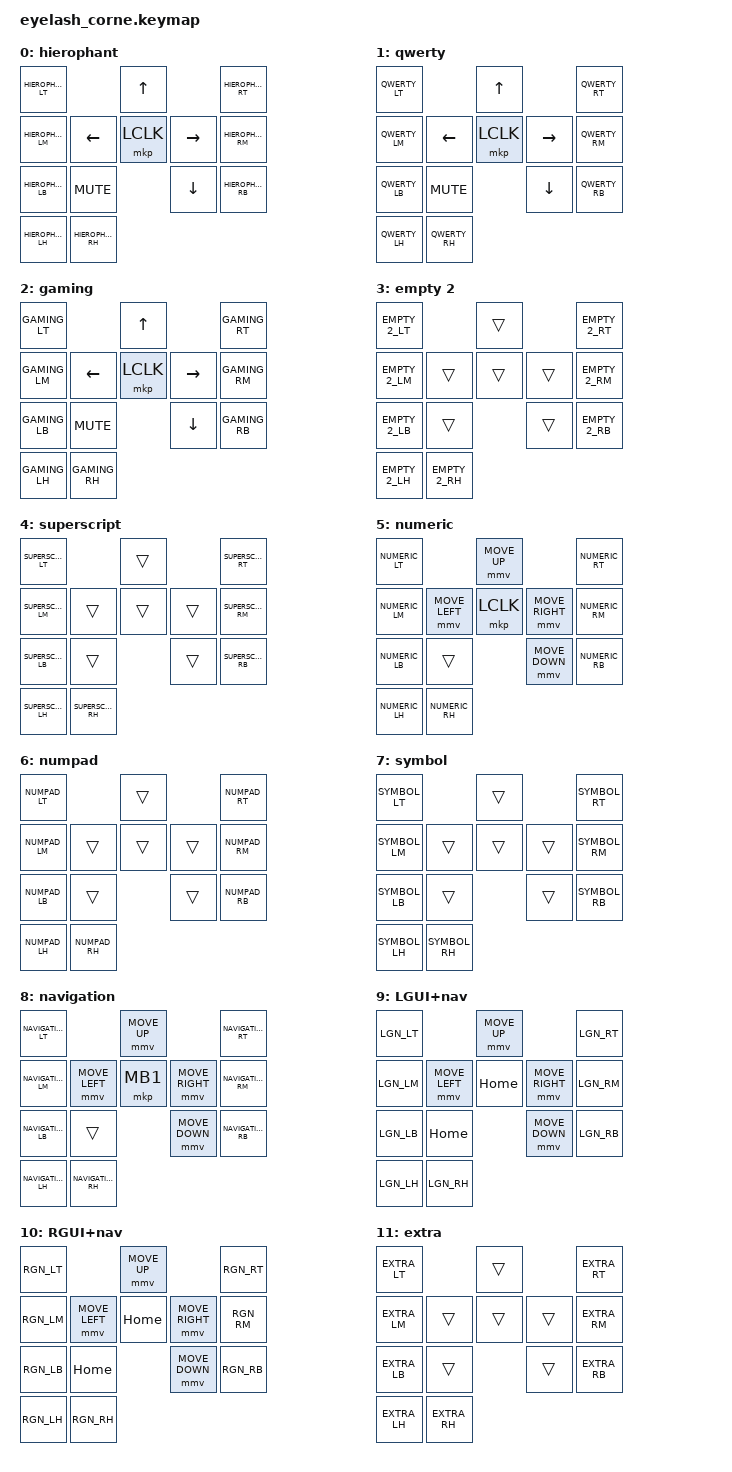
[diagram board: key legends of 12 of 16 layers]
#define INNER_CLUSTER JS0 LEC JS1 JS2 JS3 JS4

#define CONFIG_WIRELESS
#define ZMK_BASE_LAYER(name, LT, RT, LM, RM, LB, RB, LH, RH, INNER_CLUSTER)    \
    ZMK_LAYER(                                                                 \
        name,                                                                  \
                 LT RT                                                         \
                 LM RM                                                         \
                 LB RB                                                         \
                 LH RH                                                         \
	                JS0							       \
        LEC     JS1 JS2 JS3						       \
		            JS4							       \
    )

#include "zmk-helpers/key-labels/eyelash42.h"
#include "jjb.keymap"

/ {
    keymap {
        compatible = "zmk,keymap";
	hierophant_layer {
				display-name = "hierophant";
				bindings = <
HIEROPHANT_LT                       &kp UP              HIEROPHANT_RT
HIEROPHANT_LM             &kp LEFT  &mkp LCLK &kp RIGHT HIEROPHANT_RM
HIEROPHANT_LB &kp C_MUTE            &kp DOWN            HIEROPHANT_RB
HIEROPHANT_LH HIEROPHANT_RH
				>;				
            sensor-bindings = <&inc_dec_kp C_VOLUME_UP C_VOLUME_DOWN>;
	};


        qwerty_layer {
            display-name = "qwerty";
            bindings = <
QWERTY_LT                       &kp UP              QWERTY_RT
QWERTY_LM             &kp LEFT  &mkp LCLK &kp RIGHT QWERTY_RM
QWERTY_LB &kp C_MUTE            &kp DOWN            QWERTY_RB
QWERTY_LH QWERTY_RH
				>;				
        };


        gaming_layer {
            display-name = "gaming";
            bindings = <
GAMING_LT                       &kp UP              GAMING_RT
GAMING_LM             &kp LEFT  &mkp LCLK &kp RIGHT GAMING_RM
GAMING_LB &kp C_MUTE            &kp DOWN            GAMING_RB
GAMING_LH GAMING_RH
             >;
            sensor-bindings = <&inc_dec_kp C_VOLUME_UP C_VOLUME_DOWN>;
        };


	empty_2_layer {
				display-name = "empty 2";
				bindings = <
EMPTY_2_LT                &trans        EMPTY_2_RT
EMPTY_2_LM         &trans &trans &trans EMPTY_2_RM
EMPTY_2_LB &trans         &trans        EMPTY_2_RB
EMPTY_2_LH EMPTY_2_RH
				>;				
	};


        superscript_layer {
            display-name = "superscript";
            bindings = <
SUPERSCRIPT_LT                  &trans          SUPERSCRIPT_RT
SUPERSCRIPT_LM          &trans  &trans  &trans  SUPERSCRIPT_RM
SUPERSCRIPT_LB  &trans          &trans          SUPERSCRIPT_RB
SUPERSCRIPT_LH SUPERSCRIPT_RH
            >;
        };


        numeric_layer {
            display-name = "numeric";
            bindings = <
NUMERIC_LT                        &mmv MOVE_UP                NUMERIC_RT
NUMERIC_LM         &mmv MOVE_LEFT &mkp LCLK  &mmv MOVE_RIGHT  NUMERIC_RM
NUMERIC_LB &trans                 &mmv MOVE_DOWN              NUMERIC_RB
NUMERIC_LH NUMERIC_RH
            >;
            sensor-bindings = <&scroll_encoder>;
        };


        numpad_layer {
            display-name = "numpad";
            bindings = <
NUMPAD_LT                  &trans          NUMPAD_RT
NUMPAD_LM          &trans  &trans  &trans  NUMPAD_RM
NUMPAD_LB  &trans          &trans          NUMPAD_RB
NUMPAD_LH NUMPAD_RH
            >;
        };


        symbol_layer {
            display-name = "symbol";
            bindings = <
SYMBOL_LT                  &trans          SYMBOL_RT
SYMBOL_LM          &trans  &trans  &trans  SYMBOL_RM
SYMBOL_LB  &trans          &trans          SYMBOL_RB
SYMBOL_LH SYMBOL_RH
            >;
        };


        navigation_layer {
            display-name = "navigation";
            bindings = <
NAVIGATION_LT                        &mmv MOVE_UP                NAVIGATION_RT
NAVIGATION_LM         &mmv MOVE_LEFT &mkp MB1   &mmv MOVE_RIGHT  NAVIGATION_RM
NAVIGATION_LB &trans                 &mmv MOVE_DOWN              NAVIGATION_RB
NAVIGATION_LH NAVIGATION_RH
            >;
            sensor-bindings = <&scroll_encoder>;
        };


        mod_l_nav_layer {
            display-name = "LGUI+nav";
            bindings = <
LGN_LT                          &mmv MOVE_UP                      LGN_RT
LGN_LM            &mmv MOVE_LEFT &kp HOME        &mmv MOVE_RIGHT  LGN_RM
LGN_LB  &kp HOME                &mmv MOVE_DOWN                    LGN_RB
LGN_LH LGN_RH
            >;
        };


        mod_r_nav_layer {
            display-name = "RGUI+nav";
            bindings = <
RGN_LT                          &mmv MOVE_UP                      RGN_RT
RGN_LM            &mmv MOVE_LEFT &kp HOME        &mmv MOVE_RIGHT  RGN_RM
RGN_LB  &kp HOME                &mmv MOVE_DOWN                    RGN_RB
RGN_LH RGN_RH
            >;
        };


        extra_layer {
            display-name = "extra";
            bindings = <
EXTRA_LT                &trans         EXTRA_RT
EXTRA_LM         &trans &trans &trans  EXTRA_RM
EXTRA_LB &trans         &trans         EXTRA_RB
EXTRA_LH EXTRA_RH
            >;
            sensor-bindings = <&scroll_encoder>;
        };


        function_layer {
            display-name = "function";
            bindings = <
FUNCTION_LT                        &mmv MOVE_UP                FUNCTION_RT
FUNCTION_LM         &mmv MOVE_LEFT &mkp MB1   &mmv MOVE_RIGHT  FUNCTION_RM
FUNCTION_LB &trans                 &mmv MOVE_DOWN              FUNCTION_RB
FUNCTION_LH FUNCTION_RH
            >;
            sensor-bindings = <&scroll_encoder>;
        };

        lighting_layer {
            display-name = "lighting";
            bindings = <
LIGHTING_LT                            &trans                          LIGHTING_RT
LIGHTING_LM              &trans        &to HIEROPHANT   &trans         LIGHTING_RM
LIGHTING_LB  LIGHT_TOG                 &trans                          LIGHTING_RB
LIGHTING_LH LIGHTING_RH
            >;
            sensor-bindings = <&lighting_encoder>;
        };


        bluetooth_layer {
            display-name = "bluetooth";
            bindings = <
BLUETOOTH_LT                  &trans          BLUETOOTH_RT
BLUETOOTH_LM          &trans  &trans  &trans  BLUETOOTH_RM
BLUETOOTH_LB  &trans          &trans          BLUETOOTH_RB
BLUETOOTH_LH BLUETOOTH_RH
            >;
        };


        system_layer {
            display-name = "system";
            bindings = <
SYSTEM_LT                              &mmv MOVE_UP                     SYSTEM_RT
SYSTEM_LM              &mmv MOVE_LEFT  &to HIEROPHANT    &mmv MOVE_RIGHT  SYSTEM_RM
SYSTEM_LB  &kp C_MUTE                  &mmv MOVE_DOWN                   SYSTEM_RB
SYSTEM_LH SYSTEM_RH
            >;
        };



/*
        empty_layer {
            display-name = "empty";
            bindings = <
EMPTY_LT                  &trans          EMPTY_RT
EMPTY_LM          &trans  &trans  &trans  EMPTY_RM
EMPTY_LB  &trans          &trans          EMPTY_RB
EMPTY_LH EMPTY_RH
            >;
            sensor-bindings = <&scroll_encoder>;
        };
*/

     }; /* keymap */
}; // root node


